# D1H register map
Vendor: Allwinner; File version: 1.0
Registers are 32-bit, read-write, reset 0x0 unless marked. A register's access mark holds for its fields unless they carry their own. Offsets are from the block's base; [hi:lo] are bit positions; lines under a group give offsets from that group; {n}, {i} and the like mark numbered series.

## DSP_MSGBOX — DSP Message Box
Base 0x01701000
Same registers: RV_MSGBOX 0x0601F000
{0x0+0x100*i} msgbox{i} (i=0..1) group — Communicate with CPU[N]
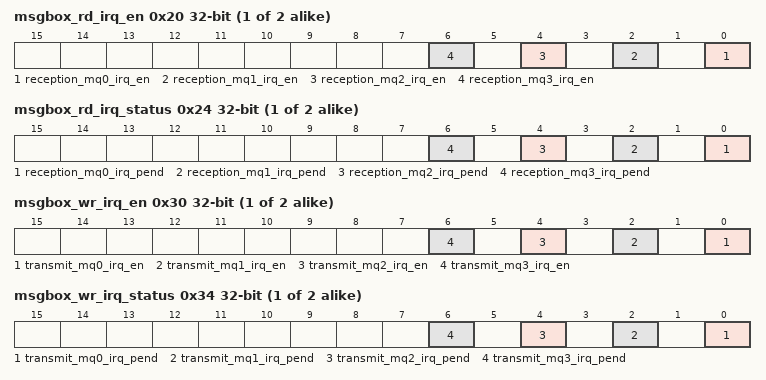
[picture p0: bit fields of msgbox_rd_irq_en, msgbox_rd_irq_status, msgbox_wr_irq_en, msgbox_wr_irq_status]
  0x20 msgbox_rd_irq_en — Message Box Read Interrupt Enable Register
    [2n] reception_mq{n}_irq_en (n=0..3) — Reception Channel[i] Interrupt Enable
      0=DISABLE; 1=ENABLE
  0x24 msgbox_rd_irq_status — Message Box Read Interrupt Status Register
    [2n] reception_mq{n}_irq_pend (n=0..3) write-1-clears — Reception Channel[i] Interrupt Pending
      0=NO_EFFECT; 1=PENDING
  0x30 msgbox_wr_irq_en — Message Box Write Interrupt Enable Register
    [2n] transmit_mq{n}_irq_en (n=0..3) — Transmit Channel[i] Interrupt Enable
      0=DISABLE; 1=ENABLE
  0x34 msgbox_wr_irq_status — Message Box Write Interrupt Status Register
    [2n] transmit_mq{n}_irq_pend (n=0..3) write-1-clears — Transmit Channel[i] Interrupt Pending
      0=NO_EFFECT; 1=PENDING
  0x40 msgbox_debug — Message Box Debug Register
  {0x50+4j} msgbox_fifo_status{j} (j=0..3) ro — Message Box FIFO Status Register
    [0] fifo_not_ava_flag — FIFO Not Available Flag
      0=AVAILABLE (The Message FIFO queue empty level reaches the configured threshold); 1=NOT_AVAILABLE (The Message FIFO queue empty level does not reach the configured threshold)
  {0x60+4j} msgbox_msg_status{j} (j=0..3) ro — Message Box Message Status Register
    [3:0] msg_num — Message Number . Number of unread messages in the message queue. Here, limit to eight messages per message queue.
  {0x70+4j} msgbox_msg{j} (j=0..3) — Message Box Message Queue Register
    [31:0] msg_que — The message register stores the next to be read message of the message FIFO queue.
  {0x80+4j} msgbox_wr_int_threshold{j} (j=0..3) — Message Box Write Interrupt Threshold Register
    [1:0] msg_wr_int_threshold_cfg — Configure the FIFO empty level to trigger the write interrupt for user1
      0=T1; 1=T2; 2=T4; 3=T8

## SPINLOCK
Base 0x03005000
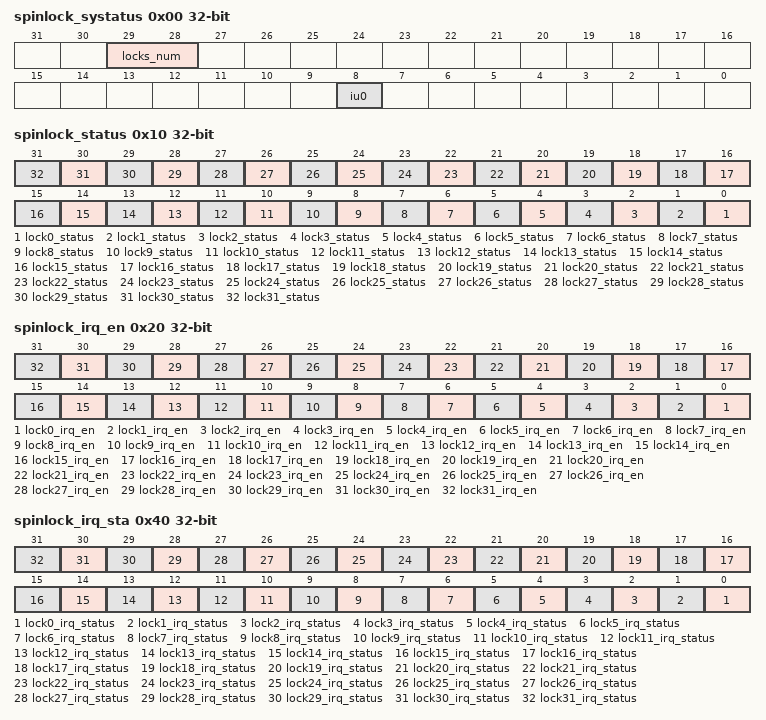
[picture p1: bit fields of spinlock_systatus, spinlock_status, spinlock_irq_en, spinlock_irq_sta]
0x00 spinlock_systatus ro — Spinlock System Status Register
  [29:28] locks_num — Number of lock registers implemented
    0=N256 (256 lock registers); 1=N32 (32 lock registers); 2=N64 (64 lock registers); 3=N128 (128 lock registers)
  [8] iu0 — In-Use flag0
    0=ALL_NOT_TAKEN (All lock registers 0-31 are not taken); 1=AT_LEAST_ONE_TAKEN (At least one of the lock registers 0-31 is taken)
0x10 spinlock_status ro
  [n] lock{n}_status (n=0..31) — Lock[i] status
    0=FREE; 1=TAKEN
0x20 spinlock_irq_en — Spinlock Interrupt Enable Register
  [n] lock{n}_irq_en (n=0..31) — Lock[i] Interrupt Enable
    0=DISABLED; 1=ENABLED
0x40 spinlock_irq_sta — Spinlock Interrupt Status Register
  [n] lock{n}_irq_status (n=0..31) write-1-clears — Lock[i] Interrupt Status
    0=NO_EFFECT; 1=PENDING
{0x80+4i} spinlock_lockid{i} (i=0..4) ro
{0x100+4i} spinlock_lock{i} (i=0..31) — Spinlock Register
  [0] taken — Lock State
    0=FREE (Read 0x0: The lock was previously Not Taken (free). The requester is granted the lock. . Write 0x0: Set the lock to Not Taken (free).); 1=TAKEN (Read 0x1: The lock was previously Taken. The requester is not granted the lock and must retry. . Write 0x1: No update to the lock value.)

## TVE_TOP — TV Encoder TOP
Base 0x05600000
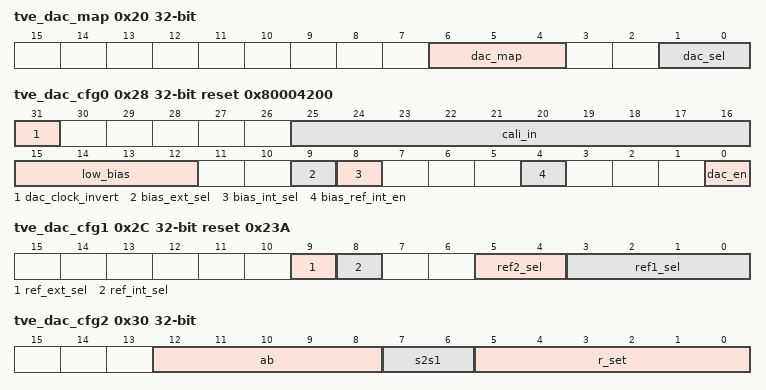
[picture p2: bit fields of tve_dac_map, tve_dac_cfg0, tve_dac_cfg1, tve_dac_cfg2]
0x20 tve_dac_map — TV Encoder DAC MAP Register
  [6:4] dac_map
    0=OUT0
  [1:0] dac_sel
    1=TVE0
0x24 tve_dac_status — TV Encoder DAC STAUTS Register
  [1:0] dac_status ro
    0=U_NCONNECTED; 1=C_ONNECTED; 3=S_HORT (Short to ground)
0x28 tve_dac_cfg0 reset 0x80004200 — TV Encoder DAC CFG0 Register
  [31] dac_clock_invert
    0=NOT_INVERT; 1=INVERT
  [25:16] cali_in
  [15:12] low_bias — 500 uA to 4 mA
  [9] bias_ext_sel — (A_SEL_BIAS_ADDA)
    0=DISABLE; 1=ENABLE
  [8] bias_int_sel — (A_SEL_BIAS_RES)
    0=DISABLE; 1=ENABLE
  [4] bias_ref_int_en — (A_EN_RESREF)
    0=DISABLE; 1=ENABLE
  [0] dac_en
    0=DISABLE; 1=ENABLE
0x2C tve_dac_cfg1 reset 0x23A — TV Encoder DAC CFG1 Register
  [9] ref_ext_sel — (A_SEL_DETREF_LDO)
    0=DISABLE; 1=ENABLE
  [8] ref_int_sel — (A_SEL_DETREF_RES)
    0=DISABLE; 1=ENABLE
  [5:4] ref2_sel — (a_refslct2[1:0])
    0=0_25_V; 1=0_30_V; 2=0_35_V; 3=0_40_V
  [3:0] ref1_sel — (a_refslct1[3:0]) . The reference voltage is used for hot plug detect function.
    0=0_50_V; 1=0_55_V; 2=0_60_V; 3=0_65_V; 4=0_70_V; 5=0_75_V; 6=0_80_V; 7=0_85_V; 8=0_90_V; 9=0_95_V; 10=1_00_V; 11=1_05_V; 12=1_10_V; 13=1_15_V; 14=1_20_V; 15=1_25_V
0x30 tve_dac_cfg2 — TV Encoder DAC CFG2 Register
  [12:8] ab — (I config output current for different peak voltage)
  [7:6] s2s1
  [5:0] r_set
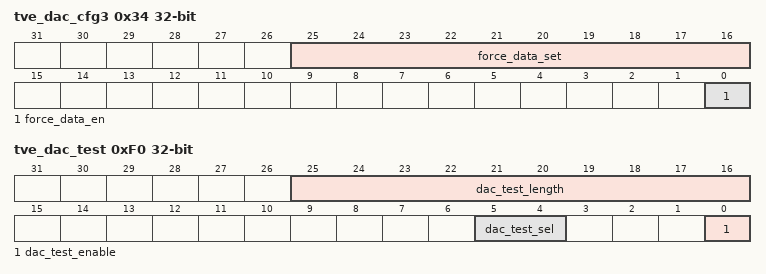
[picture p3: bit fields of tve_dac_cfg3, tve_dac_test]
0x34 tve_dac_cfg3 — TV Encoder DAC CFG2 Register
  [25:16] force_data_set — Force DAC input data
  [0] force_data_en
    0=TVE (DAC input data from TVE); 1=FORCE_DATA_SET (DAC input data from FORCE_DATA_SET)
0xF0 tve_dac_test — TV Encoder DAC TEST Register
  [25:16] dac_test_length — DAC TEST DATA LENGTH
  [5:4] dac_test_sel
    0=DAC0
  [0] dac_test_enable
    1=R_EPEAT (Repeat DAC data from DAC sram)
